# TC37XPD register map
Vendor: Infineon; Series: ATVMC; File version: 100
CPU: other r0p0, little endian, MPU, FPU, vendor SysTick, 4 interrupt priority bits
Registers are 32-bit, read-write, reset 0x0 unless marked. A register's access mark holds for its fields unless they carry their own. Offsets are from the block's base; [hi:lo] are bit positions; lines under a group give offsets from that group; {n}, {i} and the like mark numbered series; 'fields as' and 'values as' point back to an identical list.

## GETH (part 6 of 7)
Base 0xF001D000
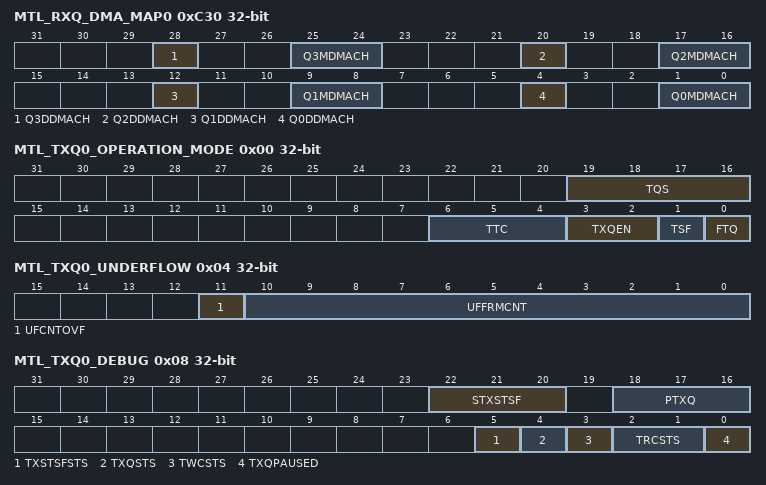
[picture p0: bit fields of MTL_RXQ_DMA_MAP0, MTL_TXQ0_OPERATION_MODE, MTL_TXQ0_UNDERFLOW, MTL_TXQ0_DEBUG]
0xC30 MTL_RXQ_DMA_MAP0 — MTL Receive Queue and DMA Channel Mapping 0 Register resetvalue={Application Reset:0x0}
  [28] Q3DDMACH — Queue 3 Enabled for Dynamic per packet DMA Channel Selection Q3DDMACH. When set this bit indicates that the packets received in Queue 3 are routed to a particular DMA channel as decided in the MAC Receiver based on the DMA channel number programmed in the L3 L4 filter registers or the Ethernet DA address. When reset this bit indicates that the packets received in Queue 3 are routed to the DMA Channel programmed in the Q3MDMACH field Bits 26 24 . Value After Reset 0x0
  [25:24] Q3MDMACH — Queue 3 Mapped to DMA Channel Q3MDMACH. This field controls the routing of the received packet in Queue 3 to the DMA channel This field is valid when the Q3DDMACH field is reset. The width of this field depends on the number of RX DMA channels and not all the values may be valid in some configurations. For example if the number of RX DMA channels selected is 2 only 000 and 001 are valid the others are reserved Value After Reset 0x0
  [20] Q2DDMACH — Queue 2 Enabled for DA based DMA Channel Selection Q2DDMACH. When set this bit indicates that the packets received in Queue 2 are routed to a particular DMA channel as decided in the MAC Receiver based on the DMA channel number programmed in the L3 L4 filter registers or the Ethernet DA address. When reset this bit indicates that the packets received in Queue 2 are routed to the DMA Channel programmed in the Q2MDMACH field Bits 18 16 . Value After Reset 0x0
  [17:16] Q2MDMACH — Queue 2 Mapped to DMA Channel Q2MDMACH. This field controls the routing of the received packet in Queue 2 to the DMA channel This field is valid when the Q2DDMACH field is reset. Value After Reset 0x0
  [12] Q1DDMACH — Queue 1 Enabled for DA based DMA Channel Selection Q1DDMACH. When set this bit indicates that the packets received in Queue 1 are routed to a particular DMA channel as decided in the MAC Receiver based on the DMA channel number programmed in the L3 L4 filter registers or the Ethernet DA address. When reset this bit indicates that the packets received in Queue 1 are routed to the DMA Channel programmed in the Q1MDMACH field Bits 10 8 . Value After Reset 0x0
  [9:8] Q1MDMACH — Queue 1 Mapped to DMA Channel Q1MDMACH. This field controls the routing of the received packet in Queue 1 to the DMA channel This field is valid when the Q1DDMACH field is reset. The width of this field depends on the number of RX DMA channels and not all the values may be valid in some configurations. For example if the number of RX DMA channels selected is 2 only 000 and 001 are valid the other bits are reserved. Value After Reset 0x0
  [4] Q0DDMACH — Queue 0 Enabled for DA based DMA Channel Selection Q0DDMACH. When set this bit indicates that the packets received in Queue 0 are routed to a particular DMA channel as decided in the MAC Receiver based on the DMA channel number programmed in the L3 L4 filter registers or the Ethernet DA address. When reset this bit indicates that the packets received in Queue 0 are routed to the DMA Channel programmed in the Q0MDMACH field. Value After Reset 0x0
  [1:0] Q0MDMACH — Queue 0 Mapped to DMA Channel Q0MDMACH. This field controls the routing of the packet received in Queue 0 to the DMA channel This field is valid when the Q0DDMACH field is reset. The width of this field depends on the number of RX DMA channels and not all the values may be valid in some configurations. For example if the number of RX DMA channels selected is 2 only 000 and 001 are valid the other bits are reserved. Value After Reset 0x0
0xD00 MTL_TXQ0 group
  0x00 MTL_TXQ0_OPERATION_MODE — MTL Queue 0 Transmit Operation Mode Register resetvalue={Application Reset:0x0}
    [19:16] TQS — Transmit Queue Size TQS. This field indicates the size of the allocated Transmit queues in blocks of 256 bytes. The TQS field is read write only if the number of Tx Queues more than one the reset value is 0x0 and indicates size of 256 bytes. When the number of Tx Queues is one the field is read only and the configured TX FIFO size in blocks of 256 bytes is reflected in the reset value. The width of this field depends on the Tx memory size selected in your configuration. For example if the memory size is 2048 the width of this field is 3 bits LOG2 2048 256 LOG2 8 3 bits Value After Reset 0x0
    [6:4] TTC — Transmit Threshold Control TTC. These bits control the threshold level of the MTL Tx Queue. The transmission starts when the packet size within the MTL Tx Queue is larger than the threshold. In addition full packets with length less than the threshold are also transmitted. These bits are used only when the TSF bit is reset. Value After Reset 0x0
    [3:2] TXQEN — Transmit Queue Enable TXQEN. This field is used to enable disable the transmit queue 0. This field is Read Only in Single Queue configurations and Read Write in Multiple Queue configurations. Note In multiple Tx queues configuration all the queues are disabled by default. Enable the Tx queue by programming this field. Value After Reset 0x0
    [1] TSF — Transmit Store and Forward TSF. When this bit is set the transmission starts when a full packet resides in the MTL Tx queue. When this bit is set the TTC values specified in Bits 6 4 of this register are ignored. This bit should be changed only when the transmission is stopped. Value After Reset 0x0
    [0] FTQ — Flush Transmit Queue FTQ. When this bit is set the Tx queue controller logic is reset to its default values. Therefore all the data in the Tx queue is lost or flushed. This bit is internally reset when the flushing operation is complete. Until this bit is reset you should not write to the MTL TxQ1 Operation Mode register. The data which is already accepted by the MAC transmitter is not flushed. It is scheduled for transmission and results in underflow and runt packet transmission. Note The flush operation is complete only when the Tx queue is empty and the application has accepted the pending Tx Status of all transmitted packets. To complete this flush operation the PHY Tx clock clk tx i should be active. Access restriction applies. Setting 1 sets. Self cleared. Setting 0 has no effect. Value After Reset 0x0
  0x04 MTL_TXQ0_UNDERFLOW ro — MTL Queue 0 Transmit Underflow Counter Register resetvalue={Application Reset:0x0}
    [11] UFCNTOVF — Overflow Bit for Underflow Packet Counter UFCNTOVF. This bit is set every time the Tx queue Underflow Packet Counter field overflows that is it has crossed the maximum count. In such a scenario the overflow packet counter is reset to all zeros and this bit indicates that the rollover happened. Access restriction applies. Clears on read. Self set to 1 on internal event. Value After Reset 0x0
    [10:0] UFFRMCNT — Underflow Packet Counter UFFRMCNT. This field indicates the number of packets aborted by the controller because of Tx Queue Underflow. This counter is incremented each time the MAC aborts outgoing packet because of underflow. The counter is cleared when this register is read with mci be i 0 at 1 b1. Access restriction applies. Clears on read. Self set to 1 on internal event. Value After Reset 0x0
  0x08 MTL_TXQ0_DEBUG ro — MTL Queue 0 Transmit Debug Register resetvalue={Application Reset:0x0}
    [22:20] STXSTSF — Number of Status Words in Tx Status FIFO of Queue STXSTSF. This field indicates the current number of status in the Tx Status FIFO of this queue. When the DTXSTS bit of MTL Operation Mode register is set to 1 this field does not reflect the number of status words in Tx Status FIFO. Value After Reset 0x0
    [18:16] PTXQ — Number of Packets in the Transmit Queue PTXQ. This field indicates the current number of packets in the Tx Queue. When the DTXSTS bit of MTL Operation Mode register is set to 1 this field does not reflect the number of packets in the Transmit queue. Value After Reset 0x0
    [5] TXSTSFSTS — MTL Tx Status FIFO Full Status TXSTSFSTS. When high this bit indicates that the MTL Tx Status FIFO is full. Therefore the MTL cannot accept any more packets for transmission. Value After Reset 0x0
    [4] TXQSTS — MTL Tx Queue Not Empty Status TXQSTS. When this bit is high it indicates that the MTL Tx Queue is not empty and some data is left for transmission. Value After Reset 0x0
    [3] TWCSTS — MTL Tx Queue Write Controller Status TWCSTS. When high this bit indicates that the MTL Tx Queue Write Controller is active and it is transferring the data to the Tx Queue. Value After Reset 0x0
    [2:1] TRCSTS — MTL Tx Queue Read Controller Status TRCSTS. This field indicates the state of the Tx Queue Read Controller Value After Reset 0x0
    [0] TXQPAUSED — Transmit Queue in Pause TXQPAUSED. When this bit is high and the Rx flow control is enabled it indicates that the Tx Queue is in the Pause condition in the full duplex only mode because of the following Reception of the PFC packet for the priorities assigned to the Tx Queue when PFC is enabled Reception of 802.3x Pause packet when PFC is disabled Value After Reset 0x0
  0x14 MTL_TXQ0_ETS_STATUS ro — MTL Queue 0 Transmit Status Register resetvalue={Application Reset:0x0}
    [23:0] ABS — Average Bits per Slot This field contains the average transmitted bits per slot. ABS. When the DCB operation is enabled for Queue 0 this field is computed over every 10 million bit times slot 10 ms in 1000 Mbps 100 ms in 100 Mbps . The maximum value is 0x989680. Value After Reset 0x0
  0x18 MTL_TXQ0_QUANTUM_WEIGHT — MTL Queue 0 Transmit Quantum or Weights Register resetvalue={Application Reset:0x0}
    [20:0] ISCQW — Quantum or Weights ISCQW. When the DCB operation is enabled with DWRR algorithm for Queue 0 traffic this field contains the quantum value in bytes to be added to credit during every queue scanning cycle. The maximum value is 0x1312D0 bytes. When DCB operation is enabled with WFQ algorithm for Queue 0 traffic this field contains the weight for this queue. The maximum value is 0x3FFF where weight of 0 indicates 100 bandwidth. Bits 20 14 must be written to zero. When DCB operation or generic queueing operation is enabled with WRR algorithm for Queue 0 traffic this field contains the weight for this queue. The maximum value is 0x64. Bits 20 7 must be written to zero. Value After Reset 0x0
0xD2C MTL_Q0 group
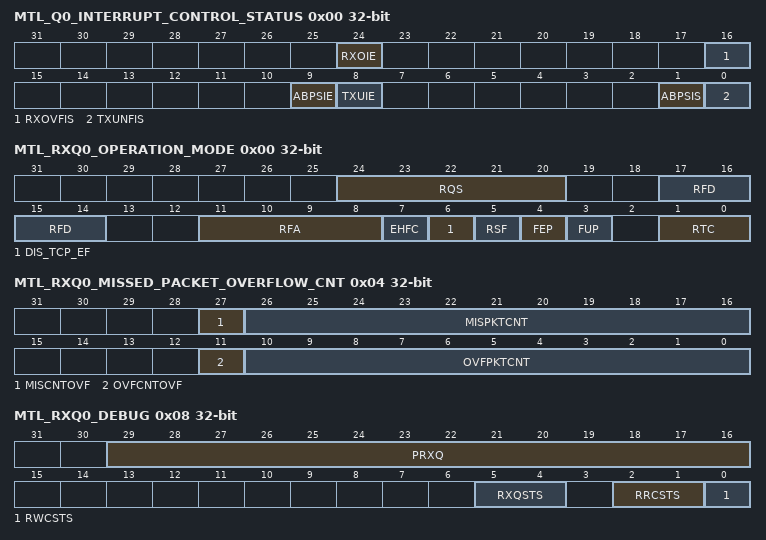
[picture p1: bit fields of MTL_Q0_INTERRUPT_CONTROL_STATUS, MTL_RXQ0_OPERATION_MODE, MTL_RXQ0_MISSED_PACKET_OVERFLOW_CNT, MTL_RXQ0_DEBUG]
  0x00 MTL_Q0_INTERRUPT_CONTROL_STATUS — MTL Queue 0 Interrupt Control Status Register resetvalue={Application Reset:0x0}
    [24] RXOIE — Receive Queue Overflow Interrupt Enable RXOIE. When this bit is set the Receive Queue Overflow interrupt is enabled. When this bit is reset the Receive Queue Overflow interrupt is disabled. Value After Reset 0x0
    [16] RXOVFIS — Receive Queue Overflow Interrupt Status RXOVFIS. This bit indicates that the Receive Queue had an overflow while receiving the packet. If a partial packet is transferred to the application the overflow status is set in RDES3 21 . This bit is cleared when the application writes 1 to this bit. Access restriction applies. Self set to 1 on internal event. Setting 1 clears. Setting 0 has no effect. Value After Reset 0x0
    [9] ABPSIE — Average Bits Per Slot Interrupt Enable ABPSIE. When this bit is set the MAC asserts the sbd intr o or mci intr o interrupt when the average bits per slot status is updated. When this bit is cleared the interrupt is not asserted for such an event. Value After Reset 0x0
    [8] TXUIE — Transmit Queue Underflow Interrupt Enable TXUIE. When this bit is set the Transmit Queue Underflow interrupt is enabled. When this bit is reset the Transmit Queue Underflow interrupt is disabled. Value After Reset 0x0
    [1] ABPSIS — Average Bits Per Slot Interrupt Status ABPSIS. When set this bit indicates that the MAC has updated the ABS value. This bit is cleared when the application writes 1 to this bit. Access restriction applies. Self set to 1 on internal event. Setting 1 clears. Setting 0 has no effect. Value After Reset 0x0
    [0] TXUNFIS — Transmit Queue Underflow Interrupt Status TXUNFIS. This bit indicates that the Transmit Queue had an underflow while transmitting the packet. Transmission is suspended and an Underflow Error TDES3 2 is set. This bit is cleared when the application writes 1 to this bit. Access restriction applies. Self set to 1 on internal event. Setting 1 clears. Setting 0 has no effect. Value After Reset 0x0
0xD30 MTL_RXQ0 group
  0x00 MTL_RXQ0_OPERATION_MODE — MTL Queue 0 Receive Operation Mode Register resetvalue={Application Reset:0x0}
    [24:20] RQS — Receive Queue Size RQS. This field indicates the size of the allocated Receive queues in blocks of 256 bytes. The RQS field is read write only if the number of Rx Queues more than one the reset value is 0x0 and indicates size of 256 bytes. When the number of Rx Queues is one the field is read only and the configured RX FIFO size in blocks of 256 bytes is reflected in the reset value. The width of this field depends on the Rx memory size selected in your configuration. For example if the memory size is 2048 the width of this field is 3 bits LOG2 2048 256 LOG2 8 3 bits Value After Reset 0x0
    [17:14] RFD — Threshold for Deactivating Flow Control in half duplex and full duplex modes RFD. These bits control the threshold fill level of Rx queue at which the flow control is de asserted after activation LOST SEQUENCE DEFINITION The de assertion is effective only after flow control is asserted. Note The value must be programmed in such a way to make sure that the threshold is a positive number. When the EHFC is set high these values are applicable only when the Rx queue size determined by the RQS field of this register is equal to or greater than 4 KB. For a given queue size the values ranges between 0 and the encoding for FULL minus QSIZE 0.5 KB and all other values are illegal. Here the term FULL and QSIZE refers to the queue size determined by the RQS field of this register. The width of this field depends on RX FIFO size selected during the configuration. Remaining bits are reserved and read only. Value After Reset 0x0
    [11:8] RFA — Threshold for Activating Flow Control in half duplex and full duplex RFA. These bits control the threshold fill level of Rx queue at which the flow control is activated For more information on encoding for this field see RFD. Value After Reset 0x0
    [7] EHFC — Enable Hardware Flow Control EHFC. When this bit is set the flow control signal operation based on the fill level of Rx queue is enabled. When reset the flow control operation is disabled. Value After Reset 0x0
    [6] DIS_TCP_EF — Disable Dropping of TCP IP Checksum Error Packets DIS TCP EF. When this bit is set the MAC does not drop the packets which only have the errors detected by the Receive Checksum Offload engine. Such packets have errors only in the encapsulated payload. There are no errors including FCS error in the Ethernet packet received by the MAC. When this bit is reset all error packets are dropped if the FEP bit is reset. Value After Reset 0x0
    [5] RSF — Receive Queue Store and Forward RSF. When this bit is set the DWC ether qos reads a packet from the Rx queue only after the complete packet has been written to it ignoring the RTC field of this register. When this bit is reset the Rx queue operates in the Threshold cut through mode subject to the threshold specified by the RTC field of this register. Value After Reset 0x0
    [4] FEP — Forward Error Packets FEP. When this bit is reset the Rx queue drops packets with error status CRC error GMII ER watchdog timeout or overflow . However if the start byte write pointer of a packet is already transferred to the read controller side in Threshold mode the packet is not dropped. When this bit is set all packets except the runt error packets are forwarded to the application or DMA. If the RSF bit is set and the Rx queue overflows when a partial packet is written the packet is dropped irrespective of the setting of this bit. However if the RSF bit is reset and the Rx queue overflows when a partial packet is written a partial packet may be forwarded to the application or DMA. Value After Reset 0x0
    [3] FUP — Forward Undersized Good Packets FUP. When this bit is set the Rx queue forwards the undersized good packets packets with no error and length less than 64 bytes including pad bytes and CRC. When this bit is reset the Rx queue drops all packets of less than 64 bytes unless a packet is already transferred because of the lower value of Rx Threshold for example RTC 01. Value After Reset 0x0
    [1:0] RTC — Receive Queue Threshold Control RTC. These bits control the threshold level of the MTL Rx queue in bytes The received packet is transferred to the application or DMA when the packet size within the MTL Rx queue is larger than the threshold. In addition full packets with length less than the threshold are automatically transferred. This field is valid only when the RSF bit is zero. This field is ignored when the RSF bit is set to 1. Value After Reset 0x0
  0x04 MTL_RXQ0_MISSED_PACKET_OVERFLOW_CNT ro — MTL Queue 0 Receive Missed Packet and Overflow Counter Register resetvalue={Application Reset:0x0}
    [27] MISCNTOVF — Missed Packet Counter Overflow Bit MISCNTOVF. When set this bit indicates that the Rx Queue Missed Packet Counter crossed the maximum limit. Access restriction applies. Clears on read. Self set to 1 on internal event. Value After Reset 0x0
    [26:16] MISPKTCNT — Missed Packet Counter MISPKTCNT. This field indicates the number of packets missed by the DWC ether qos because the application asserted ari pkt flush i for this queue. This counter is reset when this register is read with mci be i 0 at 1b1. This counter is incremented by 1 when the DMA discards the packet because of buffer unavailability. Access restriction applies. Clears on read. Self set to 1 on internal event. Value After Reset 0x0
    [11] OVFCNTOVF — Overflow Counter Overflow Bit OVFCNTOVF. When set this bit indicates that the Rx Queue Overflow Packet Counter field crossed the maximum limit. Access restriction applies. Clears on read. Self set to 1 on internal event. Value After Reset 0x0
    [10:0] OVFPKTCNT — Overflow Packet Counter OVFPKTCNT. This field indicates the number of packets discarded by the DWC ether qos because of Receive queue overflow. This counter is incremented each time the DWC ether qos discards an incoming packet because of overflow. This counter is reset when this register is read with mci be i 0 at 1 b1. Access restriction applies. Clears on read. Self set to 1 on internal event. Value After Reset 0x0
  0x08 MTL_RXQ0_DEBUG ro — MTL Queue 0 Receive Debug Register resetvalue={Application Reset:0x0}
    [29:16] PRXQ — Number of Packets in Receive Queue PRXQ. This field indicates the current number of packets in the Rx Queue. The theoretical maximum value for this field is 256KB 16B 16K Packets that is Max Queue Size Min Packet Size. Value After Reset 0x0
    [5:4] RXQSTS — MTL Rx Queue Fill Level Status RXQSTS. This field gives the status of the fill level of the Rx Queue Value After Reset 0x0
    [2:1] RRCSTS — MTL Rx Queue Read Controller State RRCSTS. This field gives the state of the Rx queue Read controller Value After Reset 0x0
    [0] RWCSTS — MTL Rx Queue Write Controller Active Status RWCSTS. When high this bit indicates that the MTL Rx queue Write controller is active and it is transferring a received packet to the Rx Queue. Value After Reset 0x0
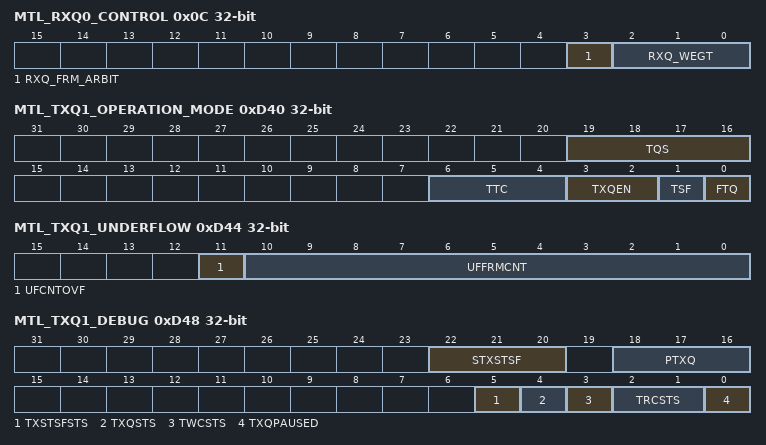
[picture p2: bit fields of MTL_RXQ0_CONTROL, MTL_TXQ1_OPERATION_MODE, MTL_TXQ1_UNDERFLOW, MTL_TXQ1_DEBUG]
  0x0C MTL_RXQ0_CONTROL — MTL Queue 0 Receive Control Register resetvalue={Application Reset:0x0}
    [3] RXQ_FRM_ARBIT — Receive Queue Packet Arbitration RXQ FRM ARBIT. When this bit is set the DWC ether qos drives the packet data to the ARI interface such that the entire packet data of currently selected queue is transmitted before switching to other queue. When this bit is reset the DWC ether qos drives the packet data to the ARI interface such that the following amount of data of currently selected queue is transmitted before switching to other queue PBL amount of data indicated by ari qN pbl i or Complete data of a packet The status and the timestamp are not a part of the PBL data. Therefore the DWC ether qos drives the complete status including timestamp status during first PBL request for the packet in store and forward mode or the last PBL request for the packet in Threshold mode . Value After Reset 0x0
    [2:0] RXQ_WEGT — Receive Queue Weight RXQ WEGT. This field indicates the weight assigned to the Rx Queue 0. The weight is used as the number of continuous PBL or packets requests depending on the RXQ FRM ARBIT allocated to the queue in one arbitration cycle. Value After Reset 0x0
0xD40 MTL_TXQ1_OPERATION_MODE — MTL Queue 3 Transmit Operation Mode Register resetvalue={Application Reset:0x0}
  [19:16] TQS — Transmit Queue Size TQS. This field indicates the size of the allocated Transmit queues in blocks of 256 bytes. The TQS field is read write only if the number of Tx Queues more than one the reset value is 0x0 and indicates size of 256 bytes. When the number of Tx Queues is one the field is read only and the configured TX FIFO size in blocks of 256 bytes is reflected in the reset value. The width of this field depends on the Tx memory size selected in your configuration. For example if the memory size is 2048 the width of this field is 3 bits LOG2 2048 256 LOG2 8 3 bits Value After Reset 0x0
  [6:4] TTC — Transmit Threshold Control TTC. These bits control the threshold level of the MTL Tx Queue. The transmission starts when the packet size within the MTL Tx Queue is larger than the threshold. In addition full packets with length less than the threshold are also transmitted. These bits are used only when the TSF bit is reset. Value After Reset 0x0
  [3:2] TXQEN — Transmit Queue Enable TXQEN. This field is used to enable disable the transmit queue 0. Note In multiple Tx queues configuration all the queues are disabled by default. Enable the Tx queue by programming this field. Value After Reset 0x0
  [1] TSF — Transmit Store and Forward TSF. When this bit is set the transmission starts when a full packet resides in the MTL Tx queue. When this bit is set the TTC values specified in Bits 6 4 of this register are ignored. This bit should be changed only when the transmission is stopped. Value After Reset 0x0
  [0] FTQ — Flush Transmit Queue FTQ. When this bit is set the Tx queue controller logic is reset to its default values. Therefore all the data in the Tx queue is lost or flushed. This bit is internally reset when the flushing operation is complete. Until this bit is reset you should not write to the MTL TxQ1 Operation Mode register. The data which is already accepted by the MAC transmitter is not flushed. It is scheduled for transmission and results in underflow and runt packet transmission. Note The flush operation is complete only when the Tx queue is empty and the application has accepted the pending Tx Status of all transmitted packets. To complete this flush operation the PHY Tx clock clk tx i should be active. Access restriction applies. Setting 1 sets. Self cleared. Setting 0 has no effect. Value After Reset 0x0
0xD44 MTL_TXQ1_UNDERFLOW ro — MTL Queue 3 Transmit Underflow Counter Register resetvalue={Application Reset:0x0}
  fields as MTL_TXQ0.MTL_TXQ0_UNDERFLOW
0xD48 MTL_TXQ1_DEBUG ro — MTL Queue 3 Transmit Debug Register resetvalue={Application Reset:0x0}
  fields as MTL_TXQ0.MTL_TXQ0_DEBUG
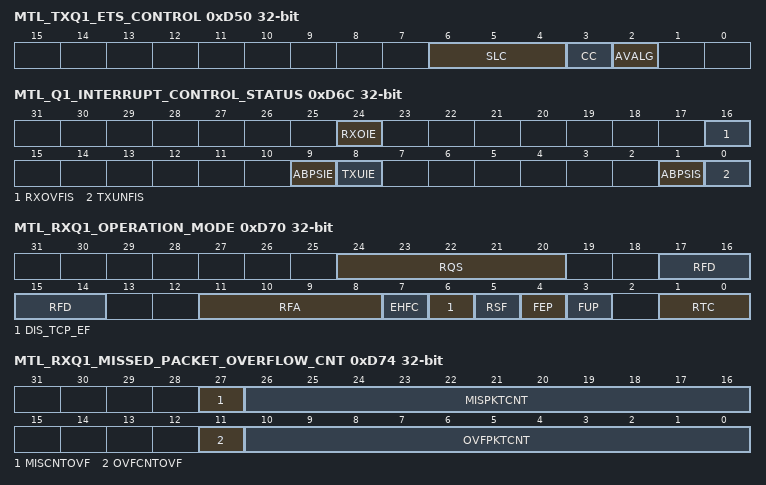
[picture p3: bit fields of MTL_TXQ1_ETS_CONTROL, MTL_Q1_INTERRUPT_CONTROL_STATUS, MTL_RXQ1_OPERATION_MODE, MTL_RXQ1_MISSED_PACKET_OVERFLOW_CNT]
0xD50 MTL_TXQ1_ETS_CONTROL — MTL Queue 3 Transmit ETS Control Register resetvalue={Application Reset:0x0}
  [6:4] SLC — Slot Count SLC. If the credit based shaper algorithm is enabled the software can program the number of slots of duration programmed in DMA CH n Slot Interval register if present or 125us over which the average transmitted bits per slot provided in the MTL TxQ n ETS Status register need to be computed for Queue. The encoding is as follows 101 111 Reserved Value After Reset 0x0
  [3] CC — Credit Control CC. When this bit is set the accumulated credit parameter in the credit based shaper algorithm logic is not reset to zero when there is positive credit and no packet to transmit in Channel 1. The credit accumulates even when there is no packet waiting in Channel 1 and another channel is transmitting. When this bit is reset the accumulated credit parameter in the credit based shaper algorithm logic is set to zero when there is positive credit and no packet to transmit in Channel 1. When there is no packet waiting in Channel 1 and other channel is transmitting no credit is accumulated. Value After Reset 0x0
  [2] AVALG — AV Algorithm AVALG. When Queue 1 is programmed for AV this field configures the scheduling algorithm for this queue This bit when set indicates credit based shaper algorithm CBS is selected for Queue 1 traffic. When reset strict priority is selected. Value After Reset 0x0
0xD54 MTL_TXQ1_ETS_STATUS ro — MTL Queue 3 Transmit ETS Status Register resetvalue={Application Reset:0x0}
  [23:0] ABS — Average Bits per Slot ABS. This field contains the average transmitted bits per slot. If AV operation is enabled this field is computed over number of slots programmed in the SLC field of MTL TxQ n ETS CONTROL register. When Enable Slot Interval feature is selected the maximum value of this field is 0x6 4000 in 100 Mbps 0x3E 8000 in 1000 Mbps and 9C 4000 in 2500 Mbps mode respectively. Otherwise the maximum value of this field is 0x30D4 in 100 Mbs 0x1E848 in 1000 Mbps and 0x4C4B4 in 2500 Mbps respectively. When the DCB operation is enabled for Queue this field is computed over every 10 million bit times slot 4 ms in 2500 Mbps 10 ms in 1000 Mbps 100 ms in 100 Mbps . The maximum value is 0x989680. This field is reserved in configurations with only one transmit queue. Value After Reset 0x0
0xD58 MTL_TXQ1_QUANTUM_WEIGHT — MTL Queue 3 Transmit Quantum or Weights Register resetvalue={Application Reset:0x0}
  [20:0] ISCQW — idleSlopeCredit Quantum or Weights ISCQW. idleSlopeCredit When AV feature is enabled this field contains the idleSlopeCredit value required for the creditbased shaper algorithm for Queue 1. This is the rate of change of credit in bits per cycle 40 ns for 100 Mbps 8 ns for 1000 Mbps 3.2 ns for 2500 Mbps when the credit is increasing. The software should program this field with computed credit in bits per cycle scaled by 1 024. The maximum value is portTransmitRate that is 0x2000 in 1000 2500 Mbps mode and 0x1000 in 100 Mbps mode. Bits 20 14 must be written to zero. Quantum When the DCB operation is enabled with DWRR algorithm for Queue 1 traffic this field contains the quantum value in bytes to be added to credit during every queue scanning cycle. The maximum value is 0x1312D0 bytes. Weights When DCB operation is enabled with WFQ algorithm for Queue 1 traffic this field contains the weight for this queue. The maximum value is 0x3FFF where weight of 0 indicates 100 bandwidth. Bits 20 14 must be written to zero. The higher the programmed weights lesser the bandwidth allocated for the particular Transmit Queue. This is because the weights are used to compute the packet finish time weights packet size . Lesser the finish time higher the probability of the packet getting scheduled first and using more bandwidth. When DCB operation or generic queueing operation is enabled with WRR algorithm for Queue 1 traffic this field contains the weight for this queue. The maximum value is 0x64. Bits 20 7 must be written to zero. Note 1 In multiple Queue configuration this field in respective per queue register must be programmed to some non zero value when multiple queues are enabled or single queue other than Q0 is enabled. This field need not be programmed when only Q0 is enabled. In general when WRR algorithm is selected a non zero value must be programmed on both Receive and Transmit. In Receive the register is MTL Operation Mode register. Note 2 For WFQ algorithm higher the programmed weights lesser the bandwidth allocated for that Transmit Queue. The finish time is not a function of particular packet alone but it is as per the formula previous finish time of particular Transmit Queue weights packet size Note 3 The weights programmed do not correspond to the number of packets but the fraction of bandwidth or time allocated for particular queue w.r.t. total BW or time. Value After Reset 0x0
0xD5C MTL_TXQ1_SENDSLOPECREDIT — MTL Queue 3 Transmit SendSlopeCredit Register resetvalue={Application Reset:0x0}
  [13:0] SSC — sendSlopeCredit Value SSC. When AV operation is enabled this field contains the sendSlopeCredit value required for credit based shaper algorithm for Queue 1. This is the rate of change of credit in bits per cycle 40 ns for 100 Mbps and 8 ns 1000 Mbps when the credit is decreasing. The software should program this field with computed credit in bits per cycle scaled by 1 024. The maximum value is portTransmitRate that is 0x2000 in 1000 Mbps mode and 0x1000 in 100 Mbps mode. This field should be programmed with absolute sendSlopeCredit value. The credit based shaper logic subtracts it from the accumulated credit when Channel 1 is selected for transmission. Value After Reset 0x0
0xD60 MTL_TXQ1_HICREDIT — MTL Queue 3 Transmit HiCredit Register resetvalue={Application Reset:0x0}
  [28:0] HC — hiCredit Value HC. When the AV feature is enabled this field contains the hiCredit value required for the credit based shaper algorithm. This is the maximum value that can be accumulated in the credit parameter. This is specified in bits scaled by 1 024. The maximum value is maxInterferenceSize that is best effort maximum packet size 16 384 bytes or 131 072 bits . The value to be specified is 131 072 1 024 134 217 728 or 0x0800 0000. Value After Reset 0x0
0xD64 MTL_TXQ1_LOCREDIT — MTL Queue 3 Transmit LoCredit Register resetvalue={Application Reset:0x0}
  [28:0] LC — loCredit Value LC. When AV operation is enabled this field contains the loCredit value required for the credit based shaper algorithm. This is the minimum value that can be accumulated in the credit parameter. This is specified in bits scaled by 1 024. The maximum value to be programmed corresponds to twice the maxFrameSize transmitted from this queue. If the maxFrameSize is 8192 bytes then 8192 2 8 1024 134 217 728 or 0x0800 0000. Because it is a negative value the programmed value is 2 s complement of the value that is 0x1800 0000. Value After Reset 0x0
0xD6C MTL_Q1_INTERRUPT_CONTROL_STATUS — MTL Queue 3 Interrupt Status Register resetvalue={Application Reset:0x0}
  fields as MTL_Q0.MTL_Q0_INTERRUPT_CONTROL_STATUS
0xD70 MTL_RXQ1_OPERATION_MODE — MTL Queue 3 Receive Operation Mode Register resetvalue={Application Reset:0x0}
  [24:20] RQS — Receive Queue Size RQS. This field indicates the size of the allocated Receive queues in blocks of 256 bytes. The RQS field is read write only if the number of Rx Queues more than one and the reset value is 0x0 and indicates size of 256 bytes. When the number of Rx Queues is one the field is read only and the configured RX FIFO size in blocks of 256 bytes is reflected in the reset value. The width of this field depends on the Rx memory size selected in your configuration. For example if the memory size is 2048 the width of this field is 3 bits LOG2 2048 256 LOG2 8 3 bits Value After Reset 0x0
  [17:14] RFD — Threshold for Deactivating Flow Control in half duplex and full duplex modes RFD. These bits control the threshold fill level of Rx queue at which the flow control is de asserted after activation LOST SEQUENCE DEFINITION The de assertion is effective only after flow control is asserted. Note The value must be programmed in such a way to make sure that the threshold is a positive number. When the EHFC is set high these values are applicable only when the Rx queue size determined by the RQS field of this register is equal to or greater than 4 KB. For a given queue size the values ranges between 0 and the encoding for FULL minus QSIZE 0.5 KB and all other values are illegal. Here the term FULL and QSIZE refers to the queue size determined by the RQS field of this register. The width of this field depends on RX FIFO size selected during the configuration. Remaining bits are reserved and read only. Value After Reset 0x0
  [11:8] RFA — Threshold for Activating Flow Control in half duplex and full duplex RFA. These bits control the threshold fill level of Rx queue at which the flow control is activated For more information on encoding for this field see RFD. Value After Reset 0x0
  [7] EHFC — Enable Hardware Flow Control EHFC. When this bit is set the flow control signal operation based on the fill level of Rx queue is enabled. When reset the flow control operation is disabled. This bit is not used reserved and always reset when the Rx queue is less than 4 KB. Value After Reset 0x0
  [6] DIS_TCP_EF — Disable Dropping of TCP IP Checksum Error Packets DIS TCP EF. When this bit is set the MAC does not drop the packets which only have the errors detected by the Receive Checksum Offload engine. Such packets have errors only in the encapsulated payload. There are no errors including FCS error in the Ethernet packet received by the MAC. When this bit is reset all error packets are dropped if the FEP bit is reset. Value After Reset 0x0
  [5] RSF — Receive Queue Store and Forward RSF. When this bit is set the DWC ether qos reads a packet from the Rx queue only after the complete packet has been written to it ignoring the RTC field of this register. When this bit is reset the Rx queue operates in the Threshold cut through mode subject to the threshold specified by the RTC field of this register. Value After Reset 0x0
  [4] FEP — Forward Error Packets FEP. When this bit is reset the Rx queue drops packets with error status CRC error GMII ER watchdog timeout or overflow . However if the start byte write pointer of a packet is already transferred to the read controller side in Threshold mode the packet is not dropped. When this bit is set all packets except the runt error packets are forwarded to the application or DMA. If the RSF bit is set and the Rx queue overflows when a partial packet is written the packet is dropped irrespective of the setting of this bit. However if the RSF bit is reset and the Rx queue overflows when a partial packet is written a partial packet may be forwarded to the application or DMA. Value After Reset 0x0
  [3] FUP — Forward Undersized Good Packets FUP. When this bit is set the Rx queue forwards the undersized good packets packets with no error and length less than 64 bytes including pad bytes and CRC. When this bit is reset the Rx queue drops all packets of less than 64 bytes unless a packet is already transferred because of the lower value of Rx Threshold for example RTC 01. Value After Reset 0x0
  [1:0] RTC — Receive Queue Threshold Control RTC. These bits control the threshold level of the MTL Rx queue in bytes The received packet is transferred to the application or DMA when the packet size within the MTL Rx queue is larger than the threshold. In addition full packets with length less than the threshold are automatically transferred. This field is valid only when the RSF bit is zero. This field is ignored when the RSF bit is set to 1. Value After Reset 0x0
0xD74 MTL_RXQ1_MISSED_PACKET_OVERFLOW_CNT ro — MTL Queue 3 Receive Missed Packet and Overflow Counter Register resetvalue={Application Reset:0x0}
  fields as MTL_RXQ0.MTL_RXQ0_MISSED_PACKET_OVERFLOW_CNT
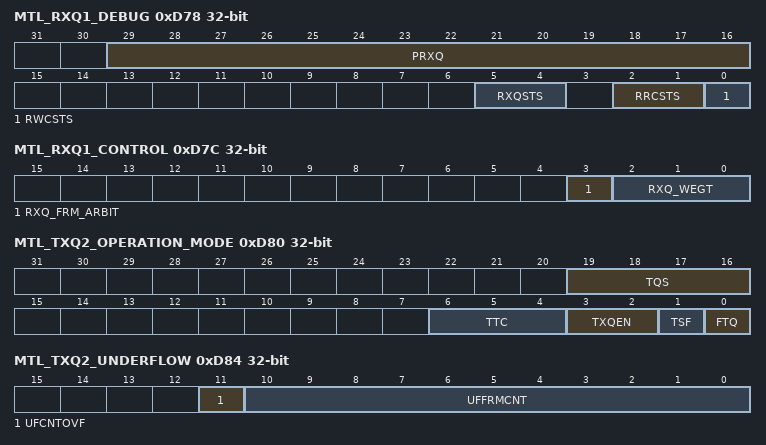
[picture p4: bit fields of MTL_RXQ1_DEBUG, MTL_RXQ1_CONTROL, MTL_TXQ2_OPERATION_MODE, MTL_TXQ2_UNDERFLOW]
0xD78 MTL_RXQ1_DEBUG ro — MTL Queue 3 Receive Debug Register resetvalue={Application Reset:0x0}
  fields as MTL_RXQ0.MTL_RXQ0_DEBUG
0xD7C MTL_RXQ1_CONTROL — MTL Queue 3 Receive Control Register resetvalue={Application Reset:0x0}
  fields as MTL_RXQ0.MTL_RXQ0_CONTROL
0xD80 MTL_TXQ2_OPERATION_MODE — MTL Queue 3 Transmit Operation Mode Register resetvalue={Application Reset:0x0}
  fields as MTL_TXQ1_OPERATION_MODE
0xD84 MTL_TXQ2_UNDERFLOW ro — MTL Queue 3 Transmit Underflow Counter Register resetvalue={Application Reset:0x0}
  fields as MTL_TXQ0.MTL_TXQ0_UNDERFLOW
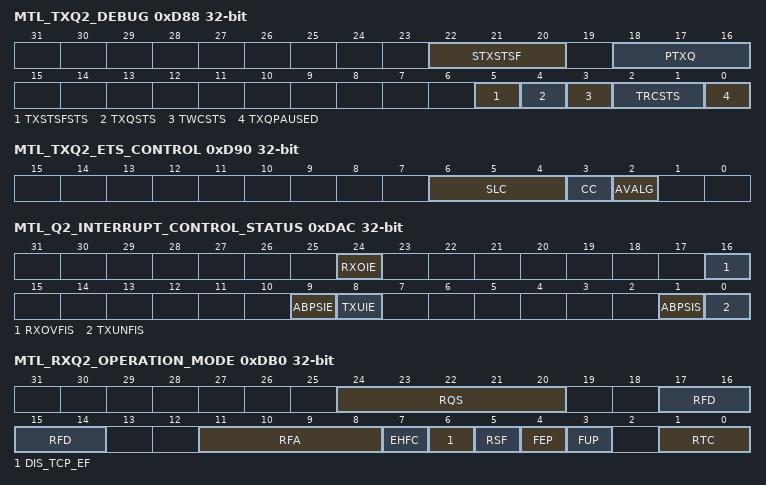
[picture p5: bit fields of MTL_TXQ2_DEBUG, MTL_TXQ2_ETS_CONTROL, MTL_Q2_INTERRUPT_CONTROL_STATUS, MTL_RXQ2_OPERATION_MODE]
0xD88 MTL_TXQ2_DEBUG ro — MTL Queue 3 Transmit Debug Register resetvalue={Application Reset:0x0}
  fields as MTL_TXQ0.MTL_TXQ0_DEBUG
0xD90 MTL_TXQ2_ETS_CONTROL — MTL Queue 3 Transmit ETS Control Register resetvalue={Application Reset:0x0}
  fields as MTL_TXQ1_ETS_CONTROL
0xD94 MTL_TXQ2_ETS_STATUS ro — MTL Queue 3 Transmit ETS Status Register resetvalue={Application Reset:0x0}
  fields as MTL_TXQ1_ETS_STATUS
0xD98 MTL_TXQ2_QUANTUM_WEIGHT — MTL Queue 3 Transmit Quantum or Weights Register resetvalue={Application Reset:0x0}
  fields as MTL_TXQ1_QUANTUM_WEIGHT
0xD9C MTL_TXQ2_SENDSLOPECREDIT — MTL Queue 3 Transmit SendSlopeCredit Register resetvalue={Application Reset:0x0}
  fields as MTL_TXQ1_SENDSLOPECREDIT
0xDA0 MTL_TXQ2_HICREDIT — MTL Queue 3 Transmit HiCredit Register resetvalue={Application Reset:0x0}
  fields as MTL_TXQ1_HICREDIT
0xDA4 MTL_TXQ2_LOCREDIT — MTL Queue 3 Transmit LoCredit Register resetvalue={Application Reset:0x0}
  fields as MTL_TXQ1_LOCREDIT
0xDAC MTL_Q2_INTERRUPT_CONTROL_STATUS — MTL Queue 3 Interrupt Status Register resetvalue={Application Reset:0x0}
  fields as MTL_Q0.MTL_Q0_INTERRUPT_CONTROL_STATUS
0xDB0 MTL_RXQ2_OPERATION_MODE — MTL Queue 3 Receive Operation Mode Register resetvalue={Application Reset:0x0}
  fields as MTL_RXQ1_OPERATION_MODE
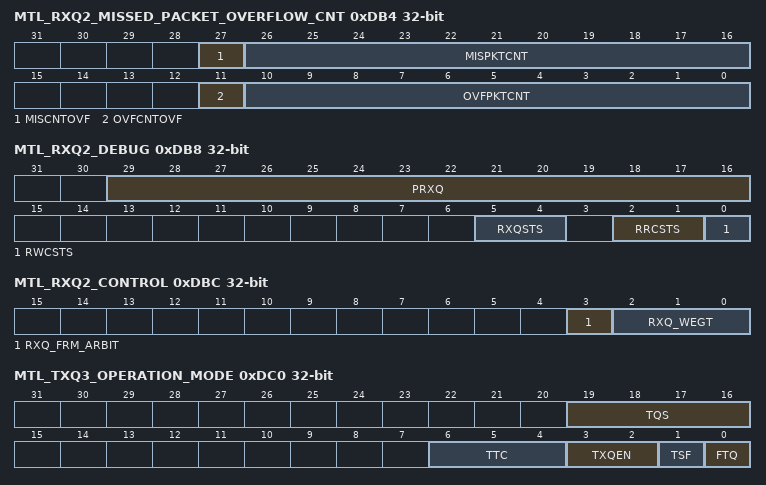
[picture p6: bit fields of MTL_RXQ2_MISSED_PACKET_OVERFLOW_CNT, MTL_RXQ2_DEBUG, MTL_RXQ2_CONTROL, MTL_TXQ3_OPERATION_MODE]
0xDB4 MTL_RXQ2_MISSED_PACKET_OVERFLOW_CNT ro — MTL Queue 3 Receive Missed Packet and Overflow Counter Register resetvalue={Application Reset:0x0}
  fields as MTL_RXQ0.MTL_RXQ0_MISSED_PACKET_OVERFLOW_CNT
0xDB8 MTL_RXQ2_DEBUG ro — MTL Queue 3 Receive Debug Register resetvalue={Application Reset:0x0}
  fields as MTL_RXQ0.MTL_RXQ0_DEBUG
0xDBC MTL_RXQ2_CONTROL — MTL Queue 3 Receive Control Register resetvalue={Application Reset:0x0}
  fields as MTL_RXQ0.MTL_RXQ0_CONTROL
0xDC0 MTL_TXQ3_OPERATION_MODE — MTL Queue 3 Transmit Operation Mode Register resetvalue={Application Reset:0x0}
  fields as MTL_TXQ1_OPERATION_MODE
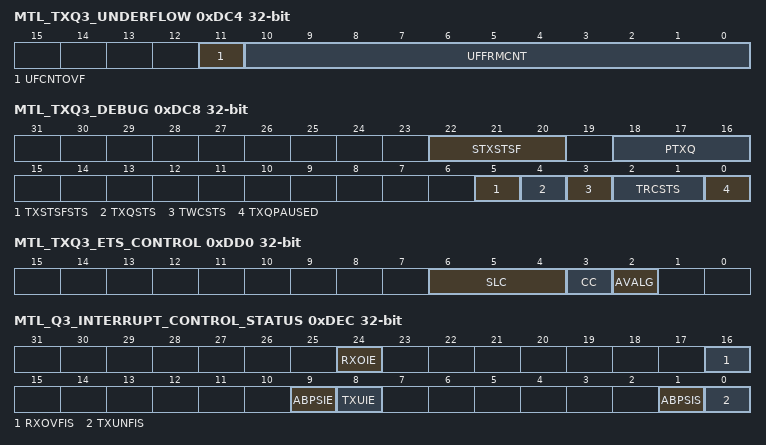
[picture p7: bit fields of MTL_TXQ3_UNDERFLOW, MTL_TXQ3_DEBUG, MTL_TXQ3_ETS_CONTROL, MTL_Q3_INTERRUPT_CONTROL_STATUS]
0xDC4 MTL_TXQ3_UNDERFLOW ro — MTL Queue 3 Transmit Underflow Counter Register resetvalue={Application Reset:0x0}
  fields as MTL_TXQ0.MTL_TXQ0_UNDERFLOW
0xDC8 MTL_TXQ3_DEBUG ro — MTL Queue 3 Transmit Debug Register resetvalue={Application Reset:0x0}
  fields as MTL_TXQ0.MTL_TXQ0_DEBUG
0xDD0 MTL_TXQ3_ETS_CONTROL — MTL Queue 3 Transmit ETS Control Register resetvalue={Application Reset:0x0}
  fields as MTL_TXQ1_ETS_CONTROL
0xDD4 MTL_TXQ3_ETS_STATUS ro — MTL Queue 3 Transmit ETS Status Register resetvalue={Application Reset:0x0}
  fields as MTL_TXQ1_ETS_STATUS
0xDD8 MTL_TXQ3_QUANTUM_WEIGHT — MTL Queue 3 Transmit Quantum or Weights Register resetvalue={Application Reset:0x0}
  fields as MTL_TXQ1_QUANTUM_WEIGHT
0xDDC MTL_TXQ3_SENDSLOPECREDIT — MTL Queue 3 Transmit SendSlopeCredit Register resetvalue={Application Reset:0x0}
  fields as MTL_TXQ1_SENDSLOPECREDIT
0xDE0 MTL_TXQ3_HICREDIT — MTL Queue 3 Transmit HiCredit Register resetvalue={Application Reset:0x0}
  fields as MTL_TXQ1_HICREDIT
0xDE4 MTL_TXQ3_LOCREDIT — MTL Queue 3 Transmit LoCredit Register resetvalue={Application Reset:0x0}
  fields as MTL_TXQ1_LOCREDIT
0xDEC MTL_Q3_INTERRUPT_CONTROL_STATUS — MTL Queue 3 Interrupt Status Register resetvalue={Application Reset:0x0}
  fields as MTL_Q0.MTL_Q0_INTERRUPT_CONTROL_STATUS
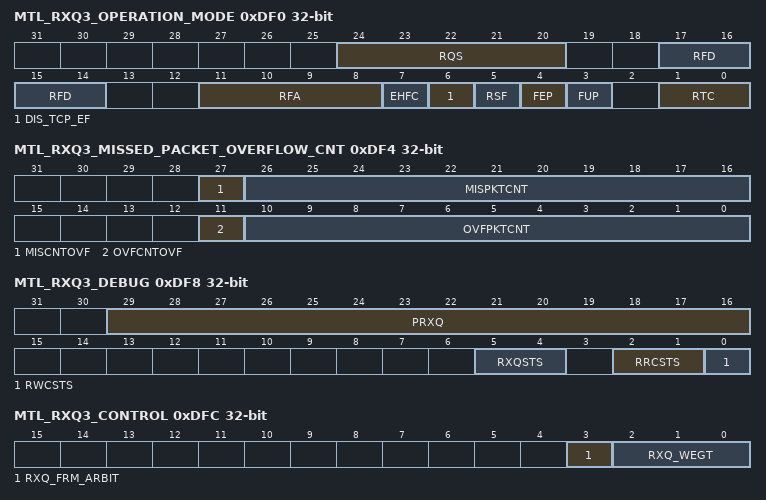
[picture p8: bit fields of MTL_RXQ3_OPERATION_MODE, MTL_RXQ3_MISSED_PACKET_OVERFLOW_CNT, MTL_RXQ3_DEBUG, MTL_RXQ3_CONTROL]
0xDF0 MTL_RXQ3_OPERATION_MODE — MTL Queue 3 Receive Operation Mode Register resetvalue={Application Reset:0x0}
  fields as MTL_RXQ1_OPERATION_MODE
0xDF4 MTL_RXQ3_MISSED_PACKET_OVERFLOW_CNT ro — MTL Queue 3 Receive Missed Packet and Overflow Counter Register resetvalue={Application Reset:0x0}
  fields as MTL_RXQ0.MTL_RXQ0_MISSED_PACKET_OVERFLOW_CNT
0xDF8 MTL_RXQ3_DEBUG ro — MTL Queue 3 Receive Debug Register resetvalue={Application Reset:0x0}
  fields as MTL_RXQ0.MTL_RXQ0_DEBUG
0xDFC MTL_RXQ3_CONTROL — MTL Queue 3 Receive Control Register resetvalue={Application Reset:0x0}
  fields as MTL_RXQ0.MTL_RXQ0_CONTROL
